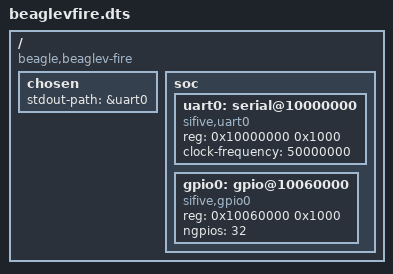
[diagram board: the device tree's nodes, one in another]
/dts-v1/;

/ {
    compatible = "beagle,beaglev-fire", "starfive,jh7110";

    chosen {
        stdout-path = &uart0;
    };

    soc {
        #address-cells = <1>;
        #size-cells = <1>;
        uart0: serial@10000000 {
            compatible = "sifive,uart0";
            reg = <0x10000000 0x1000>;
            clock-frequency = <50000000>;
            status = "okay";
        };

        gpio0: gpio@10060000 {
            compatible = "sifive,gpio0";
            reg = <0x10060000 0x1000>;
            ngpios = <32>;
            status = "okay";
        };
    };
};
